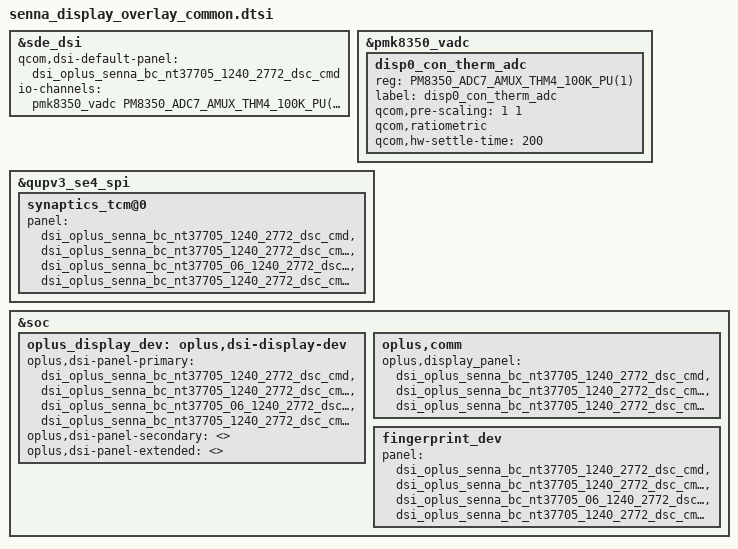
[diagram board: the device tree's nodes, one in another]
#include <dt-bindings/iio/qcom,spmi-adc7-pm8350.h>

#include "../display/dsi-panel-oplus-senna-bc-nt37705-1240-2772-dsc-cmd.dtsi"
#include "../display/dsi-panel-oplus-senna-bc-nt37705-1240-2772-dsc-cmd-04.dtsi"
#include "../display/dsi-panel-oplus-senna-bc-nt37705-06-1240-2772-dsc-cmd.dtsi"
#include "../display/dsi-panel-oplus-senna-bc-nt37705-1240-2772-dsc-cmd-evt.dtsi"

#include "../display/pxlw-senna/pxlw-iris5.dtsi"
#include "../display/pxlw-senna/dsi-panel-pxlw.dtsi"

&sde_dsi {
	qcom,dsi-default-panel = <&dsi_oplus_senna_bc_nt37705_1240_2772_dsc_cmd>;
	io-channels = <&pmk8350_vadc PM8350_ADC7_AMUX_THM4_100K_PU(1)>;
	io-channel-names = "disp0_con_therm_adc";
};

&pmk8350_vadc {
	disp0_con_therm_adc {
		reg = <PM8350_ADC7_AMUX_THM4_100K_PU(1)>;
		label = "disp0_con_therm_adc";
		qcom,pre-scaling = <1 1>;
		qcom,ratiometric;
		qcom,hw-settle-time = <200>;
	};
};

&qupv3_se4_spi {
	synaptics_tcm@0 {
		panel = <&dsi_oplus_senna_bc_nt37705_1240_2772_dsc_cmd
			&dsi_oplus_senna_bc_nt37705_1240_2772_dsc_cmd_04
			&dsi_oplus_senna_bc_nt37705_06_1240_2772_dsc_cmd
			&dsi_oplus_senna_bc_nt37705_1240_2772_dsc_cmd_evt>;
	};
};

&soc {
	oplus_display_dev: oplus,dsi-display-dev {
		oplus,dsi-panel-primary = <
			&dsi_oplus_senna_bc_nt37705_1240_2772_dsc_cmd
			&dsi_oplus_senna_bc_nt37705_1240_2772_dsc_cmd_04
			&dsi_oplus_senna_bc_nt37705_06_1240_2772_dsc_cmd
			&dsi_oplus_senna_bc_nt37705_1240_2772_dsc_cmd_evt
		>;
		oplus,dsi-panel-secondary = <>;
		oplus,dsi-panel-extended = <>;
	};

	oplus,comm {
		oplus,display_panel = <
			&dsi_oplus_senna_bc_nt37705_1240_2772_dsc_cmd
			&dsi_oplus_senna_bc_nt37705_1240_2772_dsc_cmd_evt
			&dsi_oplus_senna_bc_nt37705_1240_2772_dsc_cmd_04
		>;
	};

	fingerprint_dev {
		panel = <&dsi_oplus_senna_bc_nt37705_1240_2772_dsc_cmd
			&dsi_oplus_senna_bc_nt37705_1240_2772_dsc_cmd_04
			&dsi_oplus_senna_bc_nt37705_06_1240_2772_dsc_cmd
			&dsi_oplus_senna_bc_nt37705_1240_2772_dsc_cmd_evt>;
	};
};
